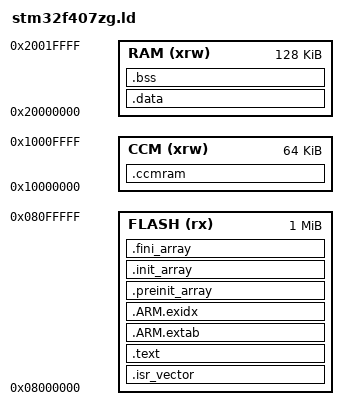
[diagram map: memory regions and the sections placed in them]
ENTRY(Reset_Handler)

MEMORY
{
    FLASH (rx)  : ORIGIN = 0x08000000, LENGTH = 1024K
    RAM   (xrw) : ORIGIN = 0x20000000, LENGTH = 128K
    CCM   (xrw) : ORIGIN = 0x10000000, LENGTH = 64K
}

_estack = ORIGIN(RAM) + LENGTH(RAM);

SECTIONS
{
    .isr_vector :
    {
        KEEP(*(.isr_vector))
    } > FLASH

    .text :
    {
        *(.text*)
        *(.rodata*)
        KEEP(*(.init))
        KEEP(*(.fini))
        . = ALIGN(4);
    } > FLASH

    .ARM.extab :
    {
        *(.ARM.extab* .gnu.linkonce.armextab.*)
    } > FLASH

    .ARM.exidx :
    {
        __exidx_start = .;
        *(.ARM.exidx* .gnu.linkonce.armexidx.*)
        __exidx_end = .;
    } > FLASH

    /* Constructor tables live in flash and are never written at runtime. */
    .preinit_array (READONLY) :
    {
        PROVIDE_HIDDEN(__preinit_array_start = .);
        KEEP(*(.preinit_array*))
        PROVIDE_HIDDEN(__preinit_array_end = .);
    } > FLASH

    .init_array (READONLY) :
    {
        PROVIDE_HIDDEN(__init_array_start = .);
        KEEP(*(SORT(.init_array.*)))
        KEEP(*(.init_array*))
        PROVIDE_HIDDEN(__init_array_end = .);
    } > FLASH

    .fini_array (READONLY) :
    {
        PROVIDE_HIDDEN(__fini_array_start = .);
        KEEP(*(SORT(.fini_array.*)))
        KEEP(*(.fini_array*))
        PROVIDE_HIDDEN(__fini_array_end = .);
    } > FLASH

    . = ALIGN(4);
    _etext = .;

    .data : AT(_etext)
    {
        . = ALIGN(4);
        _sdata = .;
        *(.data*)
        . = ALIGN(4);
        _edata = .;
    } > RAM

    .bss (NOLOAD) :
    {
        . = ALIGN(4);
        _sbss = .;
        *(.bss*)
        *(COMMON)
        . = ALIGN(4);
        _ebss = .;
    } > RAM

    . = ALIGN(8);
    _end = .;

    .ccmram (NOLOAD) :
    {
        . = ALIGN(4);
        _sccmram = .;
        *(.ccmram*)
        . = ALIGN(4);
        _eccmram = .;
    } > CCM

    /DISCARD/ :
    {
        *(.note*)
        *(.comment*)
    }
}
